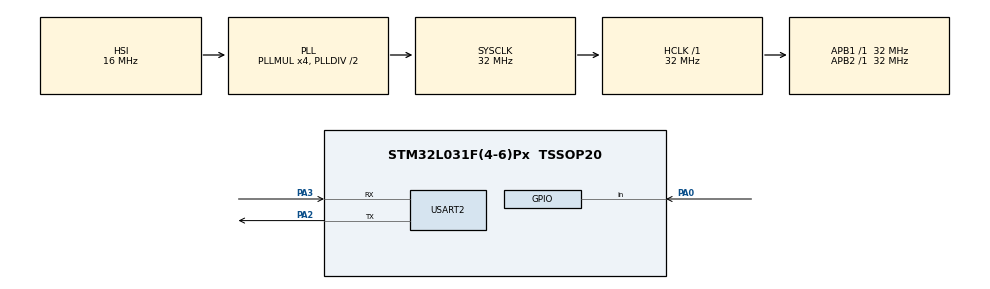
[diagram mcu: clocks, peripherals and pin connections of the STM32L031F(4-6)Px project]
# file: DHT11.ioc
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Mcu.Family=STM32L0
Mcu.Name=STM32L031F(4-6)Px
Mcu.Package=TSSOP20
NVIC.TIM2_IRQn=true\:0\:0\:false\:false\:true\:true\:true
PA0-CK_IN.GPIO_PuPd=GPIO_NOPULL
PA0-CK_IN.Signal=GPIO_Input
PA13.Mode=Serial_Wire
PA13.Signal=SYS_SWDIO
PA14.Mode=Serial_Wire
PA14.Signal=SYS_SWCLK
PA2.Mode=Asynchronous
PA2.Signal=USART2_TX
PA3.Mode=Asynchronous
PA3.Signal=USART2_RX
ProjectManager.HeapSize=0x200
ProjectManager.StackSize=0x400
ProjectManager.TargetToolchain=MDK-ARM V5.27
RCC.AHBFreq_Value=32000000
RCC.APB1Freq_Value=32000000
RCC.APB1TimFreq_Value=32000000
RCC.APB2Freq_Value=32000000
RCC.APB2TimFreq_Value=32000000
RCC.HCLKFreq_Value=32000000
RCC.HSE_VALUE=8000000
RCC.HSI16_VALUE=16000000
RCC.HSI_VALUE=16000000
RCC.LSE_VALUE=32768
RCC.MSI_VALUE=2097000
RCC.PLLMUL=RCC_PLLMUL_4
RCC.SYSCLKFreq_VALUE=32000000
RCC.SYSCLKSource=RCC_SYSCLKSOURCE_PLLCLK
RCC.VCOOutputFreq_Value=64000000
TIM2.Prescaler=31
USART2.VirtualMode-Asynchronous=VM_ASYNC
VP_TIM2_VS_ClockSourceINT.Mode=Internal
board=custom

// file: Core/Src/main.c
/* USER CODE BEGIN Header */
/**
  ******************************************************************************
  * @file           : main.c
  * @brief          : Main program body
  ******************************************************************************
  * @attention
  *
  * <h2><center>&copy; Copyright (c) 2021 STMicroelectronics.
  * All rights reserved.</center></h2>
  *
  * This software component is licensed by ST under BSD 3-Clause license,
  * the "License"; You may not use this file except in compliance with the
  * License. You may obtain a copy of the License at:
  *                        opensource.org/licenses/BSD-3-Clause
  *
  ******************************************************************************
  */
/* USER CODE END Header */
#include "main.h"

/* USER CODE BEGIN Includes */
#include "dht11.h"
#include "stdio.h"
/* USER CODE END Includes */

TIM_HandleTypeDef htim2;

UART_HandleTypeDef huart2;

/* USER CODE BEGIN PV */
#ifdef __GNUC__
  #define PUTCHAR_PROTOTYPE int __io_putchar(int ch)
#else
  #define PUTCHAR_PROTOTYPE int fputc(int ch, FILE *f)
#endif /* __GNUC__ */

PUTCHAR_PROTOTYPE
{
	HAL_UART_Transmit(&huart2, (uint8_t *)&ch, 1, 0xFFFF);
	return ch;
}
/* USER CODE END PV */

void SystemClock_Config(void);
static void MX_GPIO_Init(void);
static void MX_TIM2_Init(void);
static void MX_USART2_UART_Init(void);

/* USER CODE BEGIN 0 */
float tempData=0.00;
uint8_t humData;
/* USER CODE END 0 */

int main(void)
{

  /* MCU Configuration--------------------------------------------------------*/

  /* Reset of all peripherals, Initializes the Flash interface and the Systick. */
  HAL_Init();

  /* Configure the system clock */
  SystemClock_Config();

  /* Initialize all configured peripherals */
  MX_GPIO_Init();
  MX_TIM2_Init();
  MX_USART2_UART_Init();
  /* USER CODE BEGIN 2 */
	dht11_device dht;
	dht11_init(&dht, &htim2, GPIOA, 1<<0);
  /* USER CODE END 2 */

  /* Infinite loop */
  /* USER CODE BEGIN WHILE */
  while (1)
  {
		get_dht11_data(&dht);
		tempData=dht.temperature;
		humData=dht.humidty;
		HAL_Delay(1000);
    /* USER CODE END WHILE */

  }
}

void SystemClock_Config(void)
{
  RCC_OscInitTypeDef RCC_OscInitStruct = {0};
  RCC_ClkInitTypeDef RCC_ClkInitStruct = {0};
  RCC_PeriphCLKInitTypeDef PeriphClkInit = {0};

  /** Configure the main internal regulator output voltage
  */
  __HAL_PWR_VOLTAGESCALING_CONFIG(PWR_REGULATOR_VOLTAGE_SCALE1);
  /** Initializes the RCC Oscillators according to the specified parameters
  * in the RCC_OscInitTypeDef structure.
  */
  RCC_OscInitStruct.OscillatorType = RCC_OSCILLATORTYPE_HSI;
  RCC_OscInitStruct.HSIState = RCC_HSI_ON;
  RCC_OscInitStruct.HSICalibrationValue = RCC_HSICALIBRATION_DEFAULT;
  RCC_OscInitStruct.PLL.PLLState = RCC_PLL_ON;
  RCC_OscInitStruct.PLL.PLLSource = RCC_PLLSOURCE_HSI;
  RCC_OscInitStruct.PLL.PLLMUL = RCC_PLLMUL_4;
  RCC_OscInitStruct.PLL.PLLDIV = RCC_PLLDIV_2;
  if (HAL_RCC_OscConfig(&RCC_OscInitStruct) != HAL_OK)
  {
    Error_Handler();
  }
  /** Initializes the CPU, AHB and APB buses clocks
  */
  RCC_ClkInitStruct.ClockType = RCC_CLOCKTYPE_HCLK|RCC_CLOCKTYPE_SYSCLK
                              |RCC_CLOCKTYPE_PCLK1|RCC_CLOCKTYPE_PCLK2;
  RCC_ClkInitStruct.SYSCLKSource = RCC_SYSCLKSOURCE_PLLCLK;
  RCC_ClkInitStruct.AHBCLKDivider = RCC_SYSCLK_DIV1;
  RCC_ClkInitStruct.APB1CLKDivider = RCC_HCLK_DIV1;
  RCC_ClkInitStruct.APB2CLKDivider = RCC_HCLK_DIV1;

  if (HAL_RCC_ClockConfig(&RCC_ClkInitStruct, FLASH_LATENCY_1) != HAL_OK)
  {
    Error_Handler();
  }
  PeriphClkInit.PeriphClockSelection = RCC_PERIPHCLK_USART2;
  PeriphClkInit.Usart2ClockSelection = RCC_USART2CLKSOURCE_PCLK1;
  if (HAL_RCCEx_PeriphCLKConfig(&PeriphClkInit) != HAL_OK)
  {
    Error_Handler();
  }
}

static void MX_TIM2_Init(void)
{

  TIM_ClockConfigTypeDef sClockSourceConfig = {0};
  TIM_MasterConfigTypeDef sMasterConfig = {0};

  htim2.Instance = TIM2;
  htim2.Init.Prescaler = 31;
  htim2.Init.CounterMode = TIM_COUNTERMODE_UP;
  htim2.Init.Period = 65535;
  htim2.Init.ClockDivision = TIM_CLOCKDIVISION_DIV1;
  htim2.Init.AutoReloadPreload = TIM_AUTORELOAD_PRELOAD_DISABLE;
  if (HAL_TIM_Base_Init(&htim2) != HAL_OK)
  {
    Error_Handler();
  }
  sClockSourceConfig.ClockSource = TIM_CLOCKSOURCE_INTERNAL;
  if (HAL_TIM_ConfigClockSource(&htim2, &sClockSourceConfig) != HAL_OK)
  {
    Error_Handler();
  }
  sMasterConfig.MasterOutputTrigger = TIM_TRGO_RESET;
  sMasterConfig.MasterSlaveMode = TIM_MASTERSLAVEMODE_DISABLE;
  if (HAL_TIMEx_MasterConfigSynchronization(&htim2, &sMasterConfig) != HAL_OK)
  {
    Error_Handler();
  }

}

static void MX_USART2_UART_Init(void)
{

  huart2.Instance = USART2;
  huart2.Init.BaudRate = 115200;
  huart2.Init.WordLength = UART_WORDLENGTH_8B;
  huart2.Init.StopBits = UART_STOPBITS_1;
  huart2.Init.Parity = UART_PARITY_NONE;
  huart2.Init.Mode = UART_MODE_TX_RX;
  huart2.Init.HwFlowCtl = UART_HWCONTROL_NONE;
  huart2.Init.OverSampling = UART_OVERSAMPLING_16;
  huart2.Init.OneBitSampling = UART_ONE_BIT_SAMPLE_DISABLE;
  huart2.AdvancedInit.AdvFeatureInit = UART_ADVFEATURE_NO_INIT;
  if (HAL_UART_Init(&huart2) != HAL_OK)
  {
    Error_Handler();
  }

}

static void MX_GPIO_Init(void)
{
  GPIO_InitTypeDef GPIO_InitStruct = {0};

  /* GPIO Ports Clock Enable */
  __HAL_RCC_GPIOA_CLK_ENABLE();

  /*Configure GPIO pin : PA0 */
  GPIO_InitStruct.Pin = GPIO_PIN_0;
  GPIO_InitStruct.Mode = GPIO_MODE_INPUT;
  GPIO_InitStruct.Pull = GPIO_NOPULL;
  HAL_GPIO_Init(GPIOA, &GPIO_InitStruct);

}

void Error_Handler(void)
{
  __disable_irq();
  while (1)
  {
  }
}

/************************ (C) COPYRIGHT STMicroelectronics *****END OF FILE****/
